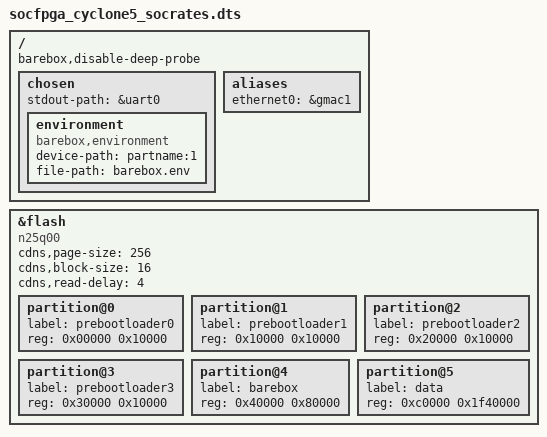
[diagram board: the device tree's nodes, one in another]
/*
 *  Copyright (C) 2013 Steffen Trumtrar <s.trumtrar@pengutronix.de>
 *
 * This program is free software; you can redistribute it and/or modify
 * it under the terms of the GNU General Public License as published by
 * the Free Software Foundation; either version 2 of the License, or
 * (at your option) any later version.
 *
 * This program is distributed in the hope that it will be useful,
 * but WITHOUT ANY WARRANTY; without even the implied warranty of
 * MERCHANTABILITY or FITNESS FOR A PARTICULAR PURPOSE.  See the
 * GNU General Public License for more details.
 *
 * You should have received a copy of the GNU General Public License
 * along with this program.  If not, see <http://www.gnu.org/licenses/>.
 */

#include <arm/intel/socfpga/socfpga_cyclone5_socrates.dts>
#include "socfpga.dtsi"

/ {
	barebox,disable-deep-probe;

	chosen {
		stdout-path = &uart0;

		environment {
			compatible = "barebox,environment";
			device-path = &mmc, "partname:1";
			file-path = "barebox.env";
		};
	};

	aliases {
		ethernet0 = &gmac1;
	};
};

&flash {
	compatible = "n25q00";
	cdns,page-size = <256>;
	cdns,block-size = <16>;
	cdns,read-delay = <4>;

	partition@0 {
		label = "prebootloader0";
		reg = <0x00000 0x10000>;
	};

	partition@1 {
		label = "prebootloader1";
		reg = <0x10000 0x10000>;
	};

	partition@2 {
		label = "prebootloader2";
		reg = <0x20000 0x10000>;
	};

	partition@3 {
		label = "prebootloader3";
		reg = <0x30000 0x10000>;
	};

	partition@4 {
		label = "barebox";
		reg = <0x40000 0x80000>;
	};

	partition@5 {
		label = "data";
		reg = <0xc0000 0x1f40000>;
	};
};
